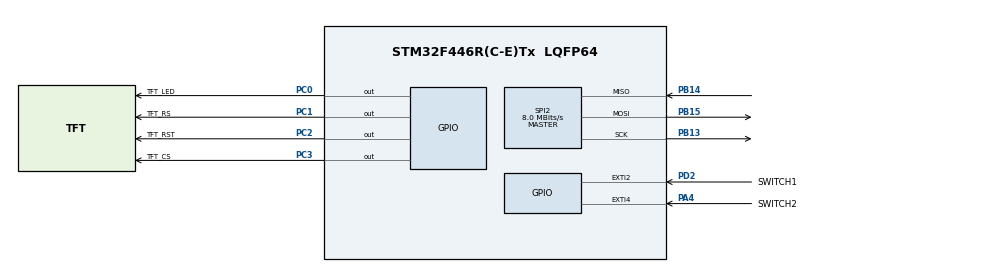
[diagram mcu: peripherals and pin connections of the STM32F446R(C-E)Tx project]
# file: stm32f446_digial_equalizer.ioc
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Mcu.Family=STM32F4
Mcu.Name=STM32F446R(C-E)Tx
Mcu.Package=LQFP64
NVIC.EXTI2_IRQn=true\:0\:0\:false\:false\:true\:true\:true\:true
NVIC.EXTI4_IRQn=true\:0\:0\:false\:false\:true\:true\:true\:true
NVIC.PriorityGroup=NVIC_PRIORITYGROUP_4
PA4.GPIO_Label=SWITCH2
PA4.GPIO_PuPd=GPIO_PULLDOWN
PA4.Signal=GPXTI4
PB12.Signal=SPI2_NSS
PB13.Mode=Full_Duplex_Master
PB13.Signal=SPI2_SCK
PB14.Mode=Full_Duplex_Master
PB14.Signal=SPI2_MISO
PB15.Mode=Full_Duplex_Master
PB15.Signal=SPI2_MOSI
PC0.GPIO_Label=TFT_LED
PC0.Signal=GPIO_Output
PC1.GPIO_Label=TFT_RS
PC1.Signal=GPIO_Output
PC2.GPIO_Label=TFT_RST
PC2.Signal=GPIO_Output
PC3.GPIO_Label=TFT_CS
PC3.Signal=GPIO_Output
PD2.GPIO_Label=SWITCH1
PD2.GPIO_PuPd=GPIO_PULLDOWN
PD2.Signal=GPXTI2
ProjectManager.HeapSize=0x200
ProjectManager.StackSize=0x400
ProjectManager.TargetToolchain=STM32CubeIDE
RCC.CortexFreq_Value=16000000
RCC.USBFreq_Value=96000000
RCC.VCOOutputFreq_Value=192000000
SPI2.CalculateBaudRate=8.0 MBits/s
SPI2.Direction=SPI_DIRECTION_2LINES
SPI2.Mode=SPI_MODE_MASTER
SPI2.VirtualType=VM_MASTER
board=custom

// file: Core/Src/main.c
/* USER CODE BEGIN Header */
/**
******************************************************************************
* @file           : main.c
* @brief          : Main program body
******************************************************************************
* @attention
*
* Copyright (c) 2025 STMicroelectronics.
* All rights reserved.
*
* This software is licensed under terms that can be found in the LICENSE file
* in the root directory of this software component.
* If no LICENSE file comes with this software, it is provided AS-IS.
*
******************************************************************************
*/
/* USER CODE END Header */
#include "main.h"

/* USER CODE BEGIN Includes */
#include "ILI9341_GFX.h"
#include "ILI9341_STM32_Driver.h"
#include "os.h"
#include "task.h"
/* USER CODE END Includes */

SPI_HandleTypeDef hspi2;

void SystemClock_Config(void);
static void MX_GPIO_Init(void);
static void MX_SPI2_Init(void);

/* USER CODE BEGIN 0 */
uint8_t task1_id;
uint8_t task2_id;
uint8_t task3_id;

// RNG_HandleTypeDef hrng;
//
SPI_HandleTypeDef hspi1;
// DMA_HandleTypeDef hdma_spi1_tx;

/* USER CODE END 0 */

int main(void)
{

  /* MCU Configuration--------------------------------------------------------*/

  /* Reset of all peripherals, Initializes the Flash interface and the Systick. */
  HAL_Init();

  /* Configure the system clock */
  SystemClock_Config();

  /* USER CODE BEGIN SysInit */
	 init_os();
  /* USER CODE END SysInit */

  /* Initialize all configured peripherals */
  MX_GPIO_Init();
  MX_SPI2_Init();
  /* USER CODE BEGIN 2 */

	 task1_id = create_task(led1_task_func, nullptr, PRIO_HIGHEST + 1, 1024);
	 task2_id = create_task(led2_task_func, nullptr, PRIO_HIGHEST + 1, 1024);
	 task3_id = create_task(led3_task_func, nullptr, PRIO_HIGHEST, 1024);

	 start_os();

  /* USER CODE END 2 */

  /* Infinite loop */
	 while (1)
	 {

	 }
}

void SystemClock_Config(void)
{
  RCC_OscInitTypeDef RCC_OscInitStruct = {0};
  RCC_ClkInitTypeDef RCC_ClkInitStruct = {0};

  /** Configure the main internal regulator output voltage
  */
  __HAL_RCC_PWR_CLK_ENABLE();
  __HAL_PWR_VOLTAGESCALING_CONFIG(PWR_REGULATOR_VOLTAGE_SCALE3);

  /** Initializes the RCC Oscillators according to the specified parameters
  * in the RCC_OscInitTypeDef structure.
  */
  RCC_OscInitStruct.OscillatorType = RCC_OSCILLATORTYPE_HSI;
  RCC_OscInitStruct.HSIState = RCC_HSI_ON;
  RCC_OscInitStruct.HSICalibrationValue = RCC_HSICALIBRATION_DEFAULT;
  RCC_OscInitStruct.PLL.PLLState = RCC_PLL_NONE;
  if (HAL_RCC_OscConfig(&RCC_OscInitStruct) != HAL_OK)
  {
    Error_Handler();
  }

  /** Initializes the CPU, AHB and APB buses clocks
  */
  RCC_ClkInitStruct.ClockType = RCC_CLOCKTYPE_HCLK|RCC_CLOCKTYPE_SYSCLK
                              |RCC_CLOCKTYPE_PCLK1|RCC_CLOCKTYPE_PCLK2;
  RCC_ClkInitStruct.SYSCLKSource = RCC_SYSCLKSOURCE_HSI;
  RCC_ClkInitStruct.AHBCLKDivider = RCC_SYSCLK_DIV1;
  RCC_ClkInitStruct.APB1CLKDivider = RCC_HCLK_DIV1;
  RCC_ClkInitStruct.APB2CLKDivider = RCC_HCLK_DIV1;

  if (HAL_RCC_ClockConfig(&RCC_ClkInitStruct, FLASH_LATENCY_0) != HAL_OK)
  {
    Error_Handler();
  }
}

static void MX_SPI2_Init(void)
{

  /* SPI2 parameter configuration*/
  hspi2.Instance = SPI2;
  hspi2.Init.Mode = SPI_MODE_MASTER;
  hspi2.Init.Direction = SPI_DIRECTION_2LINES;
  hspi2.Init.DataSize = SPI_DATASIZE_8BIT;
  hspi2.Init.CLKPolarity = SPI_POLARITY_LOW;
  hspi2.Init.CLKPhase = SPI_PHASE_1EDGE;
  hspi2.Init.NSS = SPI_NSS_SOFT;
  hspi2.Init.BaudRatePrescaler = SPI_BAUDRATEPRESCALER_2;
  hspi2.Init.FirstBit = SPI_FIRSTBIT_MSB;
  hspi2.Init.TIMode = SPI_TIMODE_DISABLE;
  hspi2.Init.CRCCalculation = SPI_CRCCALCULATION_DISABLE;
  hspi2.Init.CRCPolynomial = 10;
  if (HAL_SPI_Init(&hspi2) != HAL_OK)
  {
    Error_Handler();
  }

}

static void MX_GPIO_Init(void)
{
  GPIO_InitTypeDef GPIO_InitStruct = {0};

  /* GPIO Ports Clock Enable */
  __HAL_RCC_GPIOC_CLK_ENABLE();
  __HAL_RCC_GPIOA_CLK_ENABLE();
  __HAL_RCC_GPIOB_CLK_ENABLE();
  __HAL_RCC_GPIOD_CLK_ENABLE();

  /*Configure GPIO pin Output Level */
  HAL_GPIO_WritePin(GPIOC, TFT_LED_Pin|TFT_RS_Pin|TFT_RST_Pin|TFT_CS_Pin, GPIO_PIN_RESET);

  /*Configure GPIO pins : TFT_LED_Pin TFT_RS_Pin TFT_RST_Pin TFT_CS_Pin */
  GPIO_InitStruct.Pin = TFT_LED_Pin|TFT_RS_Pin|TFT_RST_Pin|TFT_CS_Pin;
  GPIO_InitStruct.Mode = GPIO_MODE_OUTPUT_PP;
  GPIO_InitStruct.Pull = GPIO_NOPULL;
  GPIO_InitStruct.Speed = GPIO_SPEED_FREQ_LOW;
  HAL_GPIO_Init(GPIOC, &GPIO_InitStruct);

  /*Configure GPIO pin : SWITCH2_Pin */
  GPIO_InitStruct.Pin = SWITCH2_Pin;
  GPIO_InitStruct.Mode = GPIO_MODE_IT_RISING;
  GPIO_InitStruct.Pull = GPIO_PULLDOWN;
  HAL_GPIO_Init(SWITCH2_GPIO_Port, &GPIO_InitStruct);

  /*Configure GPIO pin : SWITCH1_Pin */
  GPIO_InitStruct.Pin = SWITCH1_Pin;
  GPIO_InitStruct.Mode = GPIO_MODE_IT_RISING;
  GPIO_InitStruct.Pull = GPIO_PULLDOWN;
  HAL_GPIO_Init(SWITCH1_GPIO_Port, &GPIO_InitStruct);

  /* EXTI interrupt init*/
  HAL_NVIC_SetPriority(EXTI2_IRQn, 0, 0);
  HAL_NVIC_EnableIRQ(EXTI2_IRQn);

  HAL_NVIC_SetPriority(EXTI4_IRQn, 0, 0);
  HAL_NVIC_EnableIRQ(EXTI4_IRQn);

}

void Error_Handler(void)
{
	 __disable_irq();
	 while (1)
	 {
	 }
}
